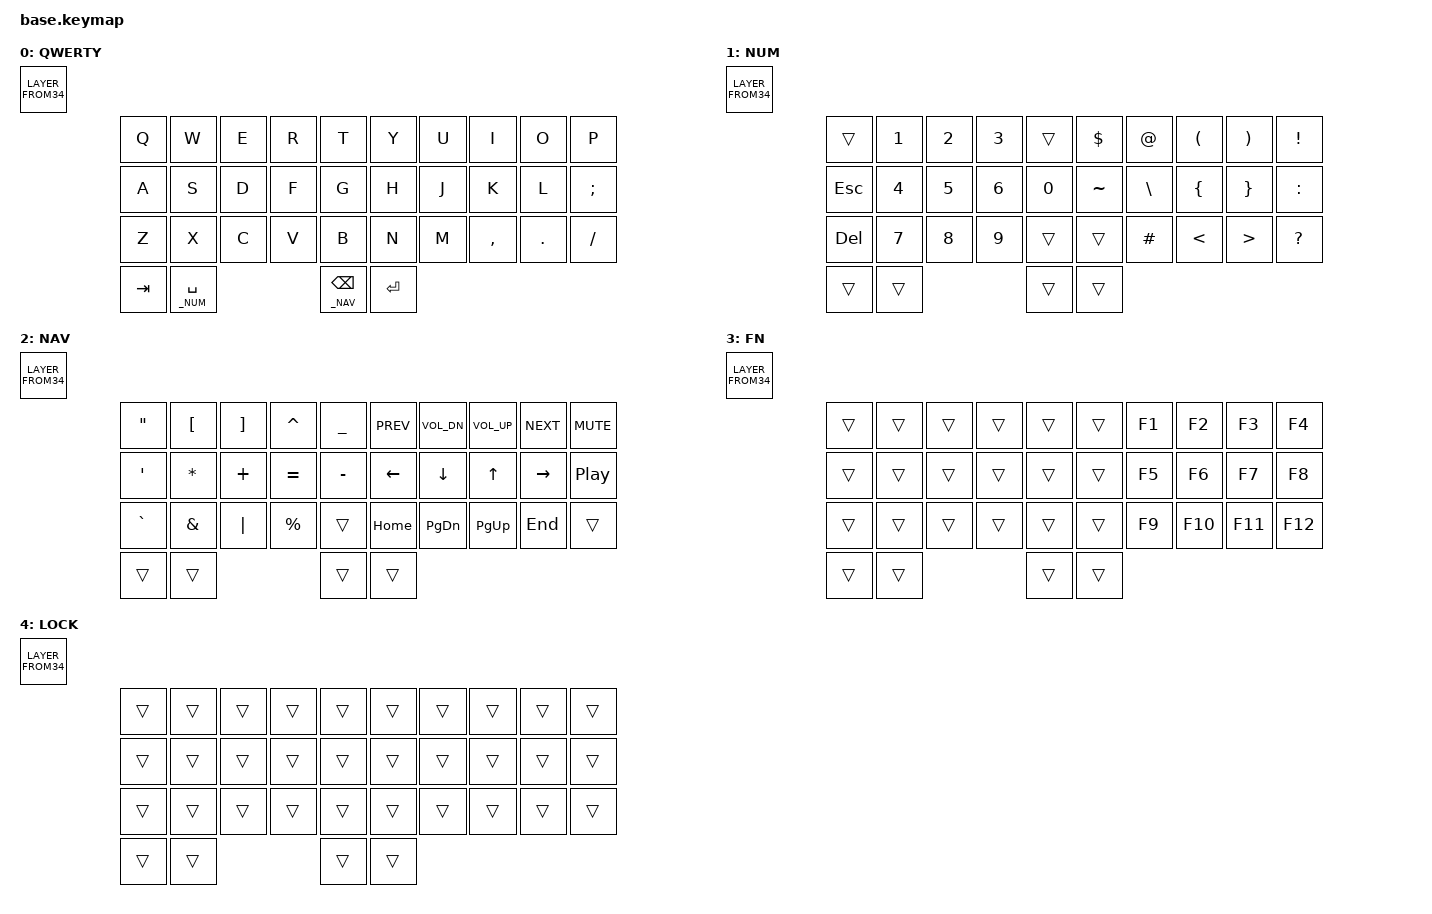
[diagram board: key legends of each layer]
#include <behaviors.dtsi>
#include <dt-bindings/zmk/keys.h>

#define _DEF 0
#define _NUM 1
#define _NAV 2
#define _FN  3
#define _LCK 4

#define ___ &trans

&lt {
    quick_tap_ms = <200>;
};

/ {
    behaviors {
        skl: sticky_key_lazy {
            compatible = "zmk,behavior-sticky-key";
            #binding-cells = <1>;
            bindings = <&kp>;
            release-after-ms = <1000>;
            lazy;
        };

        hskl: hold_sticky_key_lazy {
            compatible = "zmk,behavior-hold-tap";
            #binding-cells = <2>;
            flavor = "hold-preferred";
            tapping-term-ms = <200>;
            bindings = <&kp>, <&skl>;
        };

        td_sf_cp: tap_dance_shift_caps {
            compatible = "zmk,behavior-tap-dance";
            #binding-cells = <0>;
            // TODO: behavior is not consistent, look into it
            // we might need to change quick-tap-ms, flavor or tapping-term-ms
            // of the underlying hskl behavior. I'd bet on the first
            tapping-term-ms = <300>;
            bindings = <&hskl LSHFT LSHFT>, <&kp CAPS>;
        };
    };

    combos {
        compatible = "zmk,combos";

        // left mod combos: outer left thumb + home row key
        combo_lt1_lhi {
            timeout-ms = <50>;
            key-positions = <LH1 LM1>;
            bindings = <&td_sf_cp>;
        };

        combo_lt1_lhm {
            timeout-ms = <50>;
            key-positions = <LH1 LM2>;
            bindings = <&hskl LGUI LGUI>;
        };

        combo_lt1_lhr {
            timeout-ms = <50>;
            key-positions = <LH1 LM3>;
            bindings = <&hskl LCTRL LCTRL>;
        };

        combo_lt1_lhp {
            timeout-ms = <50>;
            key-positions = <LH1 LM4>;
            bindings = <&hskl LALT LALT>;
        };

        // right mod combos: outer right thumb + home row key
        combo_rt1_rhi {
            timeout-ms = <50>;
            key-positions = <RH1 RM1>;
            bindings = <&td_sf_cp>;
        };

        combo_rt1_rhm {
            timeout-ms = <50>;
            key-positions = <RH1 RM2>;
            bindings = <&hskl LGUI LGUI>;
        };

        combo_rt1_rhr {
            timeout-ms = <50>;
            key-positions = <RH1 RM3>;
            bindings = <&hskl LCTRL LCTRL>;
        };

        combo_rt1_rhp {
            timeout-ms = <50>;
            key-positions = <RH1 RM4>;
            bindings = <&hskl LALT LALT>;
        };

        // layer combos
        combo_lt0_lt1 {
            timeout-ms = <50>;
            key-positions = <LH1 LH0>;
            bindings = <&mo _FN>;
        };

        lock {
            timeout-ms = <50>;
            key-positions = <LH1 LT3 LH0 RT3>;
            bindings = <&tog _LCK>;
        };
    };

    keymap {
        compatible = "zmk,keymap";

        default_layer {
            display-name = "QWERTY";
//  ╭─────┬─────┬─────┬─────┬─────╮    ╭─────┬─────┬─────┬─────┬─────╮
//  │  q  │  w  │  e  │  r  │  t  │    │  y  │  u  │  i  │  o  │  p  │
//  ├─────┼─────┼─────┼─────┼─────┤    ├─────┼─────┼─────┼─────┼─────┤
//  │  a  │  s  │  d  │  f  │  g  │    │  h  │  j  │  k  │  l  │  ;  │
//  ├─────┼─────┼─────┼─────┼─────┤    ├─────┼─────┼─────┼─────┼─────┤
//  │  z  │  x  │  c  │  v  │  b  │    │  n  │  m  │  ,  │  .  │  /  │
//  ╰─────┴─────┴─────┼─────┼─────┤    ├─────┼─────┼─────┴─────┴─────╯
//                    │  ⇥  │  ␣  │    │  ⌫  │  ⏎  │
//                    ╰─────┴─────╯    ╰─────┴─────╯
            bindings = <LAYER_FROM34(
                &kp Q,  &kp W,  &kp E,  &kp R,  &kp T,   &kp Y,  &kp U,  &kp I,      &kp O,    &kp P,
                &kp A,  &kp S,  &kp D,  &kp F,  &kp G,   &kp H,  &kp J,  &kp K,      &kp L,    &kp SEMI,
                &kp Z,  &kp X,  &kp C,  &kp V,  &kp B,   &kp N,  &kp M,  &kp COMMA,  &kp DOT,  &kp FSLH,
                &kp TAB,  &lt _NUM SPACE,  &lt _NAV BSPC,  &kp RET
            )>;
        };

        number_layer {
            display-name = "NUM";
//  ╭─────┬─────┬─────┬─────┬─────╮    ╭─────┬─────┬─────┬─────┬─────╮
//  │     │  1  │  2  │  3  │     │    │  $  │  @  │  (  │  )  │  !  │
//  ├─────┼─────┼─────┼─────┼─────┤    ├─────┼─────┼─────┼─────┼─────┤
//  │  ⎋  │  4  │  5  │  6  │  0  │    │  ~  │  \  │  {  │  }  │  :  │
//  ├─────┼─────┼─────┼─────┼─────┤    ├─────┼─────┼─────┼─────┼─────┤
//  │  ⌦  │  7  │  8  │  9  │     │    │     │  #  │  <  │  >  │  ?  │
//  ╰─────┴─────┴─────┼─────┼─────┤    ├─────┼─────┼─────┴─────┴─────╯
//                    │     │     │    │     │     │
//                    ╰─────┴─────╯    ╰─────┴─────╯
            bindings = <LAYER_FROM34(
                ___,      &kp N1,  &kp N2,  &kp N3,  ___,     &kp DLLR,   &kp AT,    &kp LPAR,  &kp RPAR,  &kp EXCL,
                &kp ESC,  &kp N4,  &kp N5,  &kp N6,  &kp N0,  &kp TILDE,  &kp BSLH,  &kp LBRC,  &kp RBRC,  &kp COLON,
                &kp DEL,  &kp N7,  &kp N8,  &kp N9,  ___,     ___,        &kp HASH,  &kp LT,    &kp GT,    &kp QMARK,
                ___,  ___,  ___,  ___
            )>;
        };

        navigation_layer {
            display-name = "NAV";
//  ╭─────┬─────┬─────┬─────┬─────╮    ╭─────┬─────┬─────┬─────┬─────╮
//  │  "  │  [  │  ]  │  ^  │  _  │    │prev │ vdn │ vup │next │mute │
//  ├─────┼─────┼─────┼─────┼─────┤    ├─────┼─────┼─────┼─────┼─────┤
//  │  '  │  *  │  +  │  =  │  -  │    │  ←  │  ↓  │  ↑  │  →  │play │
//  ├─────┼─────┼─────┼─────┼─────┤    ├─────┼─────┼─────┼─────┼─────┤
//  │  `  │  &  │  |  │  %  │     │    │home │pgdn │pgup │ end │     │
//  ╰─────┴─────┴─────┼─────┼─────┤    ├─────┼─────┼─────┴─────┴─────╯
//                    │     │     │    │     │     │
//                    ╰─────┴─────╯    ╰─────┴─────╯
            bindings = <LAYER_FROM34(
                &kp DQT,    &kp LBKT,  &kp RBKT,  &kp CARET,  &kp UNDER,  &kp C_PREV,  &kp C_VOL_DN,  &kp C_VOL_UP,  &kp C_NEXT,  &kp C_MUTE,
                &kp SQT,    &kp STAR,  &kp PLUS,  &kp EQUAL,  &kp MINUS,  &kp LEFT,    &kp DOWN,      &kp UP,        &kp RIGHT,   &kp C_PP,
                &kp GRAVE,  &kp AMPS,  &kp PIPE,  &kp PRCNT,  ___,        &kp HOME,    &kp PG_DN,     &kp PG_UP,     &kp END,     ___,
                ___,  ___,  ___,  ___
            )>;
        };

        function_layer {
            display-name = "FN";
//  ╭─────┬─────┬─────┬─────┬─────╮    ╭─────┬─────┬─────┬─────┬─────╮
//  │     │     │     │     │     │    │     │ f1  │ f2  │ f3  │ f4  │
//  ├─────┼─────┼─────┼─────┼─────┤    ├─────┼─────┼─────┼─────┼─────┤
//  │     │     │     │     │     │    │     │ f5  │ f6  │ f7  │ f8  │
//  ├─────┼─────┼─────┼─────┼─────┤    ├─────┼─────┼─────┼─────┼─────┤
//  │     │     │     │     │     │    │     │ f9  │ f10 │ f11 │ f12 │
//  ╰─────┴─────┴─────┼─────┼─────┤    ├─────┼─────┼─────┴─────┴─────╯
//                    │     │     │    │     │     │
//                    ╰─────┴─────╯    ╰─────┴─────╯
            bindings = <LAYER_FROM34(
                ___,  ___,  ___,  ___,  ___,  ___,  &kp F1,   &kp F2,   &kp F3,   &kp F4,
                ___,  ___,  ___,  ___,  ___,  ___,  &kp F5,   &kp F6,   &kp F7,   &kp F8,
                ___,  ___,  ___,  ___,  ___,  ___,  &kp F9,   &kp F10,  &kp F11,  &kp F12,
                ___,  ___,  ___,  ___
            )>;
        };

        lock_layer {
            display-name = "LOCK";
            bindings = <LAYER_FROM34(
                ___,  ___,  ___,  ___,  ___,  ___,  ___,  ___,  ___,  ___,
                ___,  ___,  ___,  ___,  ___,  ___,  ___,  ___,  ___,  ___,
                ___,  ___,  ___,  ___,  ___,  ___,  ___,  ___,  ___,  ___,
                ___,  ___,  ___,  ___
            )>;
        };
    };
};
